# STM32L4x6 register map
File version: 2.0
CPU: CM4 r0p1, little endian, MPU, FPU, 4 interrupt priority bits
Registers are 32-bit, read-write, reset 0x0 unless marked. A register's access mark holds for its fields unless they carry their own. Offsets are from the block's base; [hi:lo] are bit positions; {n}, {i} and the like mark numbered series.

## FIREWALL
Base 0x40011C00
0x00 CSSA — Code segment start address
  [23:8] ADD — code segment start address
0x04 CSL — Code segment length
  [21:8] LENG — code segment length
0x08 NVDSSA — Non-volatile data segment start address
  [23:8] ADD
0x0C NVDSL — Non-volatile data segment length
  [21:8] LENG
0x10 VDSSA — Volatile data segment start address
  [15:6] ADD
0x14 VDSL — Volatile data segment length
  [15:6] LENG — Non-volatile data segment length
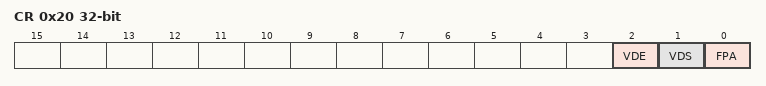
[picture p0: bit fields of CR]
0x20 CR — Configuration register
  [2] VDE — Volatile data execution
    on read: 0=NotExecutable (Volatile data segment cannot be executed if VDS = 0); 1=Executable (Volatile data segment is declared executable whatever VDS bit value) | on write: 0=Resets volatile data execution bit
  [1] VDS — Volatile data shared
    on read: 0=NotShared (Volatile data segment is not shared and cannot be hit by a non protected executable code when the Firewall is closed); 1=Shared (Volatile data segment is shared with non protected application code) | on write: 0=Resets volatile data shared bit
  [0] FPA — Firewall pre alarm
    on write: 0=PreArmReset (Any code executed outside the protected segment when the Firewall is opened will generate a system reset); 1=PreArmSet (Any code executed outside the protected segment will close the Firewall)

## DBGMCU — Debug support
Base 0xE0042000
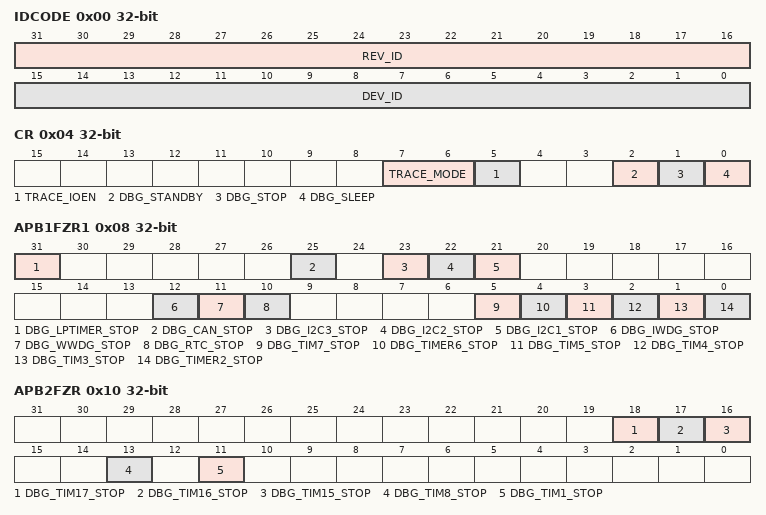
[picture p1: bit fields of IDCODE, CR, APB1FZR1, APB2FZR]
0x00 IDCODE ro — MCU Device ID Code Register
  [31:16] REV_ID — Revision Identifier
  [15:0] DEV_ID — Device Identifier
0x04 CR — Debug MCU Configuration Register
  [7:6] TRACE_MODE — Trace pin assignment control
  [5] TRACE_IOEN — Trace pin assignment control
  [2] DBG_STANDBY — Debug Standby Mode
  [1] DBG_STOP — Debug Stop Mode
  [0] DBG_SLEEP — Debug Sleep Mode
0x08 APB1FZR1 — APB Low Freeze Register 1
  [31] DBG_LPTIMER_STOP — LPTIM1 counter stopped when core is halted
  [25] DBG_CAN_STOP — bxCAN stopped when core is halted
  [23] DBG_I2C3_STOP — I2C3 SMBUS timeout counter stopped when core is halted
  [22] DBG_I2C2_STOP — I2C2 SMBUS timeout mode stopped when core is halted
  [21] DBG_I2C1_STOP — I2C1 SMBUS timeout mode stopped when core is halted
  [12] DBG_IWDG_STOP — Debug Independent Wachdog stopped when Core is halted
  [11] DBG_WWDG_STOP — Debug Window Wachdog stopped when Core is halted
  [10] DBG_RTC_STOP — Debug RTC stopped when Core is halted
  [5] DBG_TIM7_STOP — TIM7 counter stopped when core is halted
  [4] DBG_TIMER6_STOP — Debug Timer 6 stopped when Core is halted
  [3] DBG_TIM5_STOP — TIM5 counter stopped when core is halted
  [2] DBG_TIM4_STOP — TIM4 counter stopped when core is halted
  [1] DBG_TIM3_STOP — TIM3 counter stopped when core is halted
  [0] DBG_TIMER2_STOP — Debug Timer 2 stopped when Core is halted
0x0C APB1FZR2 — APB Low Freeze Register 2
  [5] DBG_LPTIM2_STOP — LPTIM2 counter stopped when core is halted
0x10 APB2FZR — APB High Freeze Register
  [18] DBG_TIM17_STOP — TIM17 counter stopped when core is halted
  [17] DBG_TIM16_STOP — TIM16 counter stopped when core is halted
  [16] DBG_TIM15_STOP — TIM15 counter stopped when core is halted
  [13] DBG_TIM8_STOP — TIM8 counter stopped when core is halted
  [11] DBG_TIM1_STOP — TIM1 counter stopped when core is halted

## SYSCFG — System configuration controller
Base 0x40010000
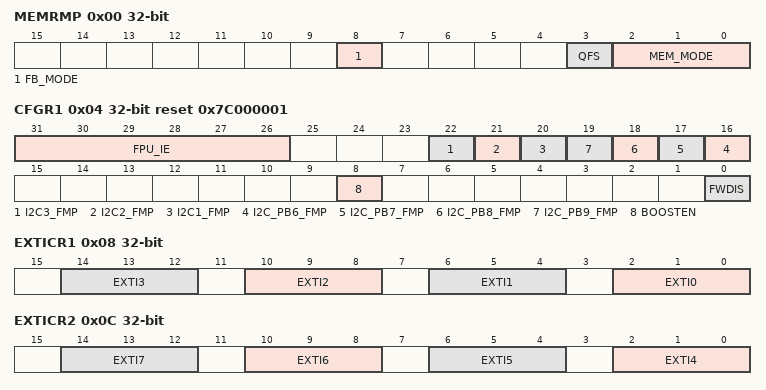
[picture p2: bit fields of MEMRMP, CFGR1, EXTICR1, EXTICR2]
0x00 MEMRMP — memory remap register
  [8] FB_MODE — Flash Bank mode selection
  [3] QFS — QUADSPI memory mapping swap
  [2:0] MEM_MODE — Memory mapping selection
0x04 CFGR1 reset 0x7C000001 — configuration register 1
  [31:26] FPU_IE — Floating Point Unit interrupts enable bits
  [22] I2C3_FMP — I2C3 Fast-mode Plus driving capability activation
  [21] I2C2_FMP — I2C2 Fast-mode Plus driving capability activation
  [20] I2C1_FMP — I2C1 Fast-mode Plus driving capability activation
  [n+10] I2C_PB{n}_FMP (n=6..9) — Fast-mode Plus (Fm+) driving capability activation on PB{n}
  [8] BOOSTEN — I/O analog switch voltage booster enable
  [0] FWDIS — Firewall disable
0x08 EXTICR1 — external interrupt configuration register 1
  [4n+2:4n] EXTI{n} (n=0..3) — EXTI {n} configuration bits
0x0C EXTICR2 — external interrupt configuration register 2
  [4n-14:4n-16] EXTI{n} (n=4..7) — EXTI {n} configuration bits
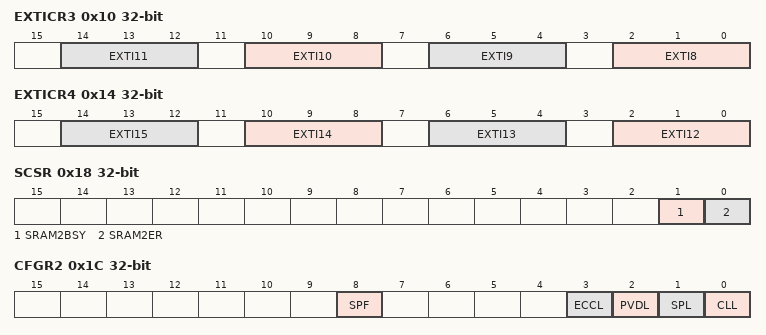
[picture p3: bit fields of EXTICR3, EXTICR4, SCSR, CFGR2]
0x10 EXTICR3 — external interrupt configuration register 3
  [4n-30:4n-32] EXTI{n} (n=8..11) — EXTI {n} configuration bits
0x14 EXTICR4 — external interrupt configuration register 4
  [4n-46:4n-48] EXTI{n} (n=12..15) — EXTI{n} configuration bits
0x18 SCSR access per field
  [1] SRAM2BSY ro — SRAM2 busy by erase operation
  [0] SRAM2ER rw — SRAM2 Erase
0x1C CFGR2 access per field
  [8] SPF rw — SRAM2 parity error flag
  [3] ECCL wo — ECC Lock
  [2] PVDL wo — PVD lock enable bit
  [1] SPL wo — SRAM2 parity lock bit
  [0] CLL wo — Cortex-M4 LOCKUP (Hardfault) output enable bit
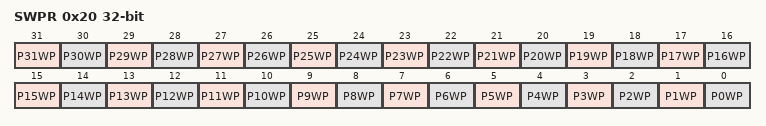
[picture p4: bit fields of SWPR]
0x20 SWPR wo
  [31] P31WP — SRAM2 page 31 write protection
  [n] P{n}WP (n=0..30)
0x24 SKR wo
  [7:0] KEY — SRAM2 write protection key for software erase
